# STM32G070 register map
File version: 1.4
CPU: CM0 r0p1, little endian, MPU, no FPU, 2 interrupt priority bits
Registers are 32-bit, read-write, reset 0x0 unless marked. A register's access mark holds for its fields unless they carry their own. Offsets are from the block's base; [hi:lo] are bit positions; {n}, {i} and the like mark numbered series; 'fields as' and 'values as' point back to an identical list.

## TIM1 — Advanced-timers
Base 0x40012C00
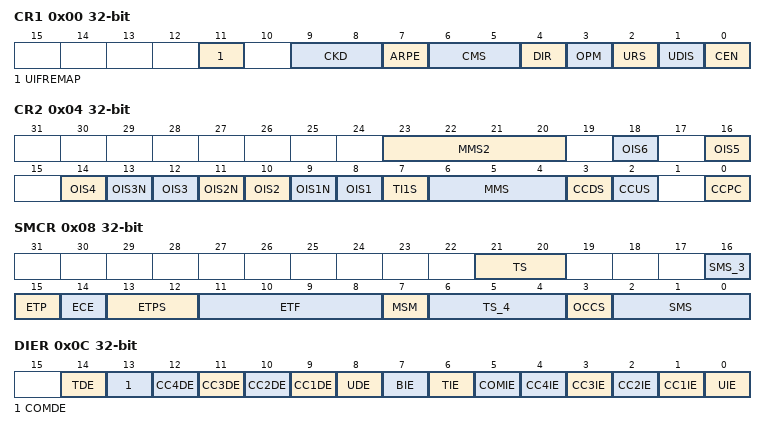
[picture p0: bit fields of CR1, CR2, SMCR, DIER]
0x00 CR1 — control register 1
  [11] UIFREMAP — UIF status bit remapping
  [9:8] CKD — Clock division
  [7] ARPE — Auto-reload preload enable
  [6:5] CMS — Center-aligned mode selection
  [4] DIR — Direction
  [3] OPM — One-pulse mode
  [2] URS — Update request source
  [1] UDIS — Update disable
  [0] CEN — Counter enable
0x04 CR2 — control register 2
  [23:20] MMS2 — Master mode selection 2
  [18] OIS6 — Output Idle state 6 (OC6 output)
  [16] OIS5 — Output Idle state 5 (OC5 output)
  [2n+6] OIS{n} (n=1..4) — Output Idle state {n}
  [13] OIS3N — Output Idle state 3
  [11] OIS2N — Output Idle state 2
  [9] OIS1N — Output Idle state 1
  [7] TI1S — TI1 selection
  [6:4] MMS — Master mode selection
  [3] CCDS — Capture/compare DMA selection
  [2] CCUS — Capture/compare control update selection
  [0] CCPC — Capture/compare preloaded control
0x08 SMCR — slave mode control register
  [21:20] TS — Trigger selection
  [16] SMS_3 — Slave mode selection - bit 3
  [15] ETP — External trigger polarity
  [14] ECE — External clock enable
  [13:12] ETPS — External trigger prescaler
  [11:8] ETF — External trigger filter
  [7] MSM — Master/Slave mode
  [6:4] TS_4 — Trigger selection
  [3] OCCS — OCREF clear selection
  [2:0] SMS — Slave mode selection
0x0C DIER — DMA/Interrupt enable register
  [14] TDE — Trigger DMA request enable
  [13] COMDE — COM DMA request enable
  [n+8] CC{n}DE (n=1..4) — Capture/Compare {n} DMA request enable
  [8] UDE — Update DMA request enable
  [7] BIE — Break interrupt enable
  [6] TIE — Trigger interrupt enable
  [5] COMIE — COM interrupt enable
  [n] CC{n}IE (n=1..4) — Capture/Compare {n} interrupt enable
  [0] UIE — Update interrupt enable
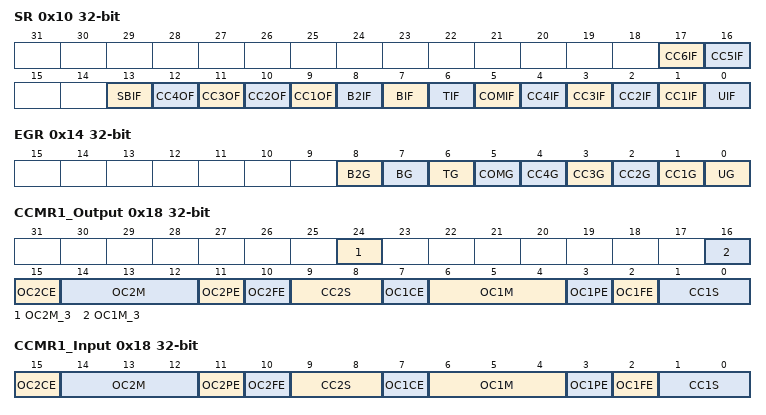
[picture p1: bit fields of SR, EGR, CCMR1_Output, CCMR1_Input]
0x10 SR — status register
  [17] CC6IF — Compare 6 interrupt flag
  [16] CC5IF — Compare 5 interrupt flag
  [13] SBIF — System Break interrupt flag
  [12] CC4OF — Capture/Compare 4 overcapture flag
  [11] CC3OF — Capture/Compare 3 overcapture flag
  [10] CC2OF — Capture/compare 2 overcapture flag
  [9] CC1OF — Capture/Compare 1 overcapture flag
  [8] B2IF — Break 2 interrupt flag
  [7] BIF — Break interrupt flag
  [6] TIF — Trigger interrupt flag
  [5] COMIF — COM interrupt flag
  [4] CC4IF — Capture/Compare 4 interrupt flag
  [3] CC3IF — Capture/Compare 3 interrupt flag
  [2] CC2IF — Capture/Compare 2 interrupt flag
  [1] CC1IF — Capture/compare 1 interrupt flag
  [0] UIF — Update interrupt flag
0x14 EGR wo — event generation register
  [8] B2G — Break 2 generation
  [7] BG — Break generation
  [6] TG — Trigger generation
  [5] COMG — Capture/Compare control update generation
  [n] CC{n}G (n=1..4) — Capture/compare {n} generation
  [0] UG — Update generation
0x18 CCMR1_Output — capture/compare mode register 1 (output mode)
  [24] OC2M_3 — Output Compare 2 mode - bit 3
    0=Normal output compare mode (modes 0-7); 1=Extended output compare mode (modes 7-15)
  [16] OC1M_3 — Output Compare 1 mode - bit 3
    values as OC2M_3
  [15] OC2CE — Output Compare 2 clear enable
  [14:12] OC2M — Output Compare 2 mode
    0=Frozen (The comparison between the output compare register TIMx_CCRy and the counter TIMx_CNT has no effect on the outputs / OpmMode1: Retriggerable OPM mode 1 - In up-counting mode, the channel is active until a trigger event is detected (on TRGI signal). In down-counting mode, the channel is inactive); 1=ActiveOnMatch (Set channel to active level on match. OCyREF signal is forced high when the counter matches the capture/compare register / OpmMode2: Inversely to OpmMode1); 2=InactiveOnMatch (Set channel to inactive level on match. OCyREF signal is forced low when the counter matches the capture/compare register / Reserved); 3=Toggle (OCyREF toggles when TIMx_CNT=TIMx_CCRy / Reserved); 4=ForceInactive (OCyREF is forced low / CombinedPwmMode1: OCyREF has the same behavior as in PWM mode 1. OCyREFC is the logical OR between OC1REF and OC2REF); 5=ForceActive (OCyREF is forced high / CombinedPwmMode2: OCyREF has the same behavior as in PWM mode 2. OCyREFC is the logical AND between OC1REF and OC2REF); 6=PwmMode1 (In upcounting, channel is active as long as TIMx_CNT<TIMx_CCRy else inactive. In downcounting, channel is inactive as long as TIMx_CNT>TIMx_CCRy else active / AsymmetricPwmMode1: OCyREF has the same behavior as in PWM mode 1. OCyREFC outputs OC1REF when the counter is counting up, OC2REF when it is counting down); 7=PwmMode2 (Inversely to PwmMode1 / AsymmetricPwmMode2: Inversely to AsymmetricPwmMode1)
  [11] OC2PE — Output Compare 2 preload enable
  [10] OC2FE — Output Compare 2 fast enable
  [9:8] CC2S — Capture/Compare 2 selection
  [7] OC1CE — Output Compare 1 clear enable
  [6:4] OC1M — Output Compare 1 mode
    values as OC2M
  [3] OC1PE — Output Compare 1 preload enable
  [2] OC1FE — Output Compare 1 fast enable
  [1:0] CC1S — Capture/Compare 1 selection
0x18 CCMR1_Input (alternate view of CCMR1_Output) — capture/compare mode register 1 (output mode)
  [15] OC2CE — Output Compare 2 clear enable
  [14:12] OC2M — Output Compare 2 mode
  [11] OC2PE — Output Compare 2 preload enable
  [10] OC2FE — Output Compare 2 fast enable
  [9:8] CC2S — Capture/Compare 2 selection
  [7] OC1CE — Output Compare 1 clear enable
  [6:4] OC1M — Output Compare 1 mode
  [3] OC1PE — Output Compare 1 preload enable
  [2] OC1FE — Output Compare 1 fast enable
  [1:0] CC1S — Capture/Compare 1 selection
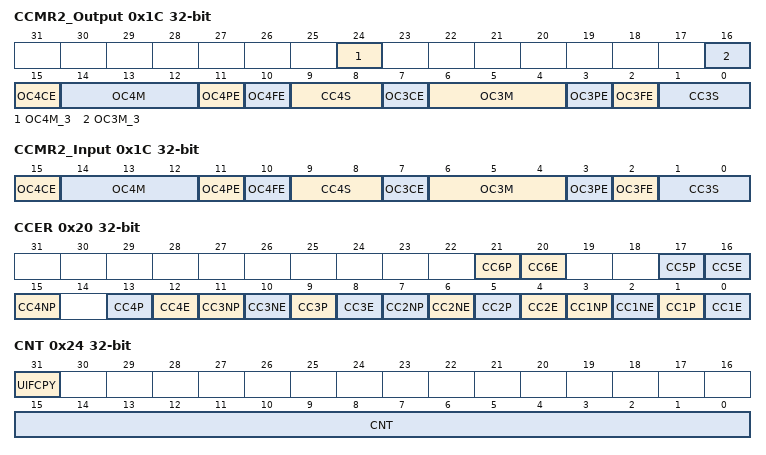
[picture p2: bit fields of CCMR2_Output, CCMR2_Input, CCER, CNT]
0x1C CCMR2_Output — capture/compare mode register 2 (output mode)
  [24] OC4M_3 — Output Compare 4 mode - bit 3
    values as CCMR1_Output.OC2M_3
  [16] OC3M_3 — Output Compare 3 mode - bit 3
    values as CCMR1_Output.OC2M_3
  [15] OC4CE — Output compare 4 clear enable
  [14:12] OC4M — Output compare 4 mode
    values as CCMR1_Output.OC2M
  [11] OC4PE — Output compare 4 preload enable
  [10] OC4FE — Output compare 4 fast enable
  [9:8] CC4S — Capture/Compare 4 selection
  [7] OC3CE — Output compare 3 clear enable
  [6:4] OC3M — Output compare 3 mode
    values as CCMR1_Output.OC2M
  [3] OC3PE — Output compare 3 preload enable
  [2] OC3FE — Output compare 3 fast enable
  [1:0] CC3S — Capture/Compare 3 selection
0x1C CCMR2_Input (alternate view of CCMR2_Output) — capture/compare mode register 2 (output mode)
  [15] OC4CE — Output compare 4 clear enable
  [14:12] OC4M — Output compare 4 mode
  [11] OC4PE — Output compare 4 preload enable
  [10] OC4FE — Output compare 4 fast enable
  [9:8] CC4S — Capture/Compare 4 selection
  [7] OC3CE — Output compare 3 clear enable
  [6:4] OC3M — Output compare 3 mode
  [3] OC3PE — Output compare 3 preload enable
  [2] OC3FE — Output compare 3 fast enable
  [1:0] CC3S — Capture/Compare 3 selection
0x20 CCER — capture/compare enable register
  [21] CC6P — Capture/Compare 6 output polarity
  [4n-4] CC{n}E (n=1..6) — Capture/Compare {n} output enable
  [17] CC5P — Capture/Compare 5 output polarity
  [15] CC4NP — Capture/Compare 4 complementary output polarity
  [13] CC4P — Capture/Compare 3 output Polarity
  [11] CC3NP — Capture/Compare 3 output Polarity
  [10] CC3NE — Capture/Compare 3 complementary output enable
  [9] CC3P — Capture/Compare 3 output Polarity
  [7] CC2NP — Capture/Compare 2 output Polarity
  [6] CC2NE — Capture/Compare 2 complementary output enable
  [5] CC2P — Capture/Compare 2 output Polarity
  [3] CC1NP — Capture/Compare 1 output Polarity
  [2] CC1NE — Capture/Compare 1 complementary output enable
  [1] CC1P — Capture/Compare 1 output Polarity
0x24 CNT access per field — counter
  [31] UIFCPY ro — UIF copy
  [15:0] CNT rw — counter value
0x28 PSC — prescaler
  [15:0] PSC — Prescaler value
0x2C ARR — auto-reload register
  [15:0] ARR — Auto-reload value
0x30 RCR — repetition counter register
  [15:0] REP — Repetition counter value
0x34 CCR1 — capture/compare register 1
  [15:0] CCR1 — Capture/Compare 1 value
0x38 CCR2 — capture/compare register 2
  [15:0] CCR2 — Capture/Compare 2 value
0x3C CCR3 — capture/compare register 3
  [15:0] CCR3 — Capture/Compare value
0x40 CCR4 — capture/compare register 4
  [15:0] CCR4 — Capture/Compare value
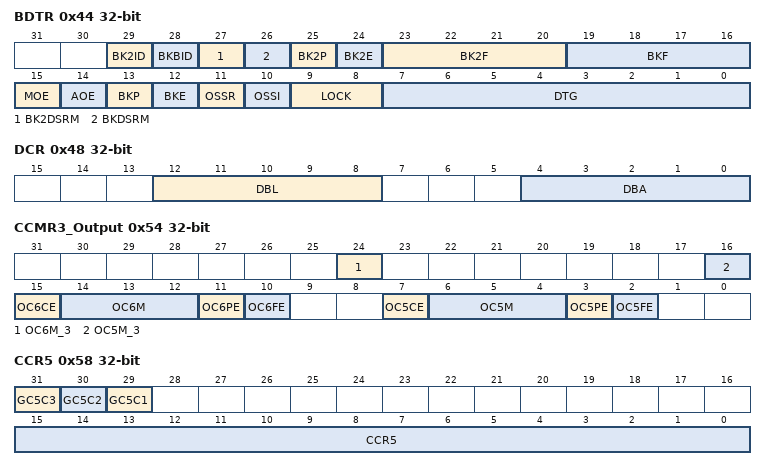
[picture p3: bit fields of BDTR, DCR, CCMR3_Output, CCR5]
0x44 BDTR — break and dead-time register
  [29] BK2ID — Break2 bidirectional
  [28] BKBID — Break Bidirectional
  [27] BK2DSRM — Break2 Disarm
  [26] BKDSRM — Break Disarm
  [25] BK2P — Break 2 polarity
  [24] BK2E — Break 2 enable
  [23:20] BK2F — Break 2 filter
  [19:16] BKF — Break filter
  [15] MOE — Main output enable
  [14] AOE — Automatic output enable
  [13] BKP — Break polarity
  [12] BKE — Break enable
  [11] OSSR — Off-state selection for Run mode
  [10] OSSI — Off-state selection for Idle mode
  [9:8] LOCK — Lock configuration
  [7:0] DTG — Dead-time generator setup
0x48 DCR — DMA control register
  [12:8] DBL — DMA burst length
  [4:0] DBA — DMA base address
0x4C DMAR — DMA address for full transfer
  [15:0] DMAB — DMA register for burst accesses
0x50 OR1 — option register 1
  [0] OCREF_CLR — Ocref_clr source selection
0x54 CCMR3_Output — capture/compare mode register 2 (output mode)
  [24] OC6M_3 — Output Compare 6 mode bit 3
    values as CCMR1_Output.OC2M_3
  [16] OC5M_3 — Output Compare 5 mode bit 3
    values as CCMR1_Output.OC2M_3
  [15] OC6CE — Output compare 6 clear enable
  [14:12] OC6M — Output compare 6 mode
    values as CCMR1_Output.OC2M
  [11] OC6PE — Output compare 6 preload enable
  [10] OC6FE — Output compare 6 fast enable
  [7] OC5CE — Output compare 5 clear enable
  [6:4] OC5M — Output compare 5 mode
    values as CCMR1_Output.OC2M
  [3] OC5PE — Output compare 5 preload enable
  [2] OC5FE — Output compare 5 fast enable
0x58 CCR5 — capture/compare register 4
  [31] GC5C3 — Group Channel 5 and Channel 3
  [30] GC5C2 — Group Channel 5 and Channel 2
  [29] GC5C1 — Group Channel 5 and Channel 1
  [15:0] CCR5 — Capture/Compare value
0x5C CCR6 — capture/compare register 4
  [15:0] CCR6 — Capture/Compare value
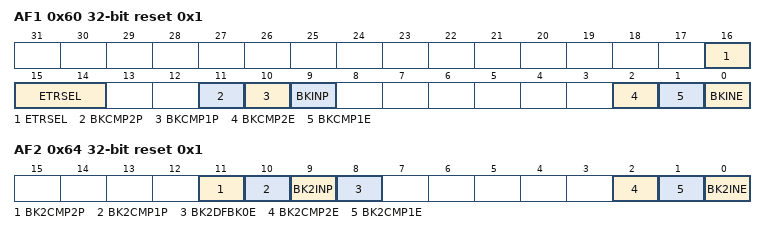
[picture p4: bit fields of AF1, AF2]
0x60 AF1 reset 0x1 — DMA address for full transfer
  [16:14] ETRSEL — ETR source selection
  [11] BKCMP2P — BRK COMP2 input polarity
  [10] BKCMP1P — BRK COMP1 input polarity
  [9] BKINP — BRK BKIN input polarity
  [2] BKCMP2E — BRK COMP2 enable
  [1] BKCMP1E — BRK COMP1 enable
  [0] BKINE — BRK BKIN input enable
0x64 AF2 reset 0x1 — DMA address for full transfer
  [11] BK2CMP2P — BRK2 COMP2 input polarity
  [10] BK2CMP1P — BRK2 COMP1 input polarity
  [9] BK2INP — BRK2 BKIN input polarity
  [8] BK2DFBK0E — BRK2 DFSDM_BREAK0 enable
  [2] BK2CMP2E — BRK2 COMP2 enable
  [1] BK2CMP1E — BRK2 COMP1 enable
  [0] BK2INE — BRK2 BKIN input enable
